# STM32WBA25xx register map
File version: 1.0
Registers are 32-bit, read-write, reset 0x0 unless marked. A register's access mark holds for its fields unless they carry their own. Offsets are from the block's base; [hi:lo] are bit positions; {n}, {i} and the like mark numbered series.

## PKA
Base 0x420C2000
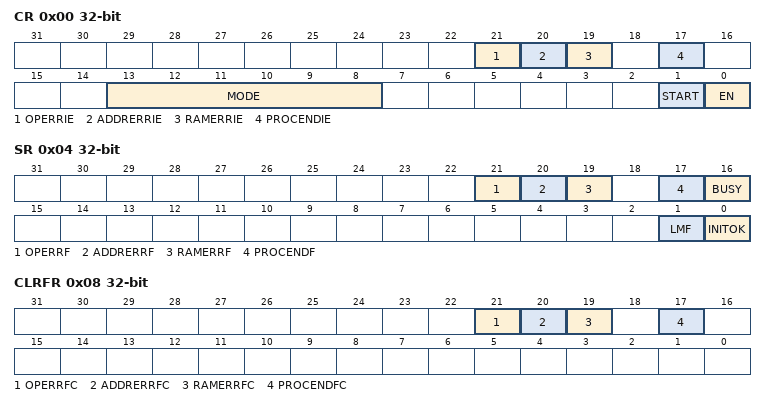
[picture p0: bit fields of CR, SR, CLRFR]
0x00 CR — PKA control register
  [21] OPERRIE — Operation Error interrupt enable
  [20] ADDRERRIE — Address error interrupt enable
  [19] RAMERRIE — RAM error interrupt enable
  [17] PROCENDIE — End of operation interrupt enable
  [13:8] MODE — MODE[5:0] PKA operation code
  [1] START — Start operation
  [0] EN — PKA enable
0x04 SR — PKA status register
  [21] OPERRF — PKA operation Error flag
  [20] ADDRERRF — Address error flag
  [19] RAMERRF — PKA RAM error flag
  [17] PROCENDF — PKA end of operation flag
  [16] BUSY — PKA operation is in progress
  [1] LMF — LMF (Limited mode flag)
  [0] INITOK — PKA initialisation flag
0x08 CLRFR — PKA clear flag register
  [21] OPERRFC — Clear PKA operation Error flag
  [20] ADDRERRFC — Clear address error flag
  [19] RAMERRFC — Clear PKA RAM error flag
  [17] PROCENDFC — Clear PKA end of operation flag
{0x400+4i} RAM[{i}] (i=0..1333)

## DLYB1
Base 0x420CF000
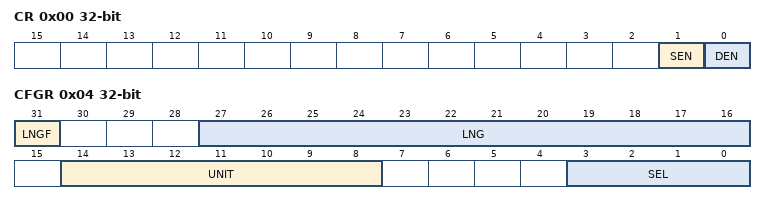
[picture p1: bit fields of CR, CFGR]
0x00 CR — DLYB control register
  [1] SEN — Sampler length enable bit
  [0] DEN — Delay block enable bit
0x04 CFGR — DLYB configuration register
  [31] LNGF — Length valid flag
  [27:16] LNG — Delay line length value
  [14:8] UNIT — Delay of a unit delay cell
  [3:0] SEL — Phase for the output clock

## XSPI1 — XSPI register block
Base 0x420D1400
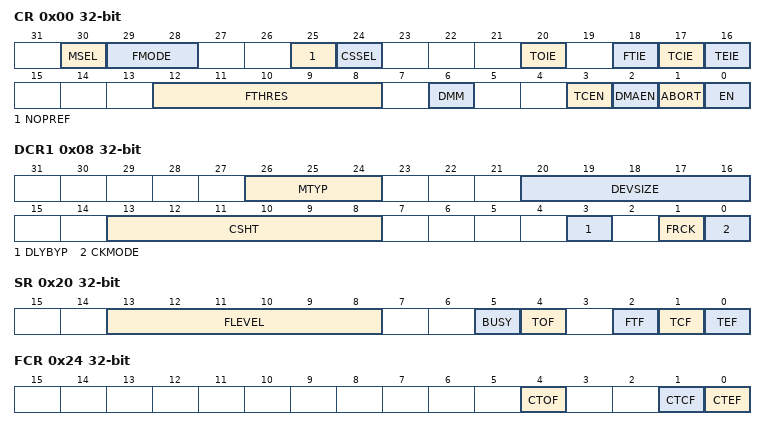
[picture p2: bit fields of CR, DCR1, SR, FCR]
0x00 CR — XSPI control register
  [30] MSEL — Flash Select
  [29:28] FMODE — FMODE[1:0] bits (Functional mode)
  [25] NOPREF — No Prefetch Data
  [24] CSSEL — Chip Select Selection
  [20] TOIE — TOIE (Timeout interrupt enable)
  [18] FTIE — FTIE (FIFO threshold interrupt enable)
  [17] TCIE — TCIE (Transfer complete interrupt enable)
  [16] TEIE — TEIE (Transfer error interrupt enable)
  [12:8] FTHRES — FTHRES[4:0] bits (FIFO threshold level)
  [6] DMM — DMM (Dual-memory configuration)
  [3] TCEN — TCEN (Timeout counter enable)
  [2] DMAEN — DMAEN (DMA enable)
  [1] ABORT — ABORT (Abort request)
  [0] EN — EN (Enable)
0x08 DCR1 — XSPI device configuration register 1
  [26:24] MTYP — MTYP[2:0] bits (Memory type)
  [20:16] DEVSIZE — DEVSIZE[4:0] bits (Device size)
  [13:8] CSHT — CSHT[5:0] bits (Chip-select high time)
  [3] DLYBYP — DLYBYP (Delay block bypass)
  [1] FRCK — FRCK (Free running clock)
  [0] CKMODE — CKMODE (Clock mode 0/mode 3)
0x0C DCR2 — XSPI device configuration register 2
  [7:0] PRESCALER — PRESCALER[7:0] bits (Clock prescaler)
0x20 SR — XSPI status register
  [13:8] FLEVEL — FLEVEL[5:0] bits (FIFO level)
  [5] BUSY — BUSY (Busy)
  [4] TOF — TOF (Timeout flag)
  [2] FTF — FTF (FIFO threshold flag)
  [1] TCF — TCF (Transfer complete flag)
  [0] TEF — TEF (Transfer error flag)
0x24 FCR — XSPI flag clear register
  [4] CTOF — CTOF (Clear timeout flag)
  [1] CTCF — CTCF (Clear transfer complete flag)
  [0] CTEF — CTEF (Clear transfer error flag)
0x40 DLR — XSPI data length register
  [31:0] DL — DL[31:0] bits (Data length)
0x48 AR — XSPI address register
  [31:0] ADDRESS — ADDRESS[31:0] bits (Address)
0x50 DR — XSPI data register
  [31:0] DATA — DATA[31:0] bits (Data)
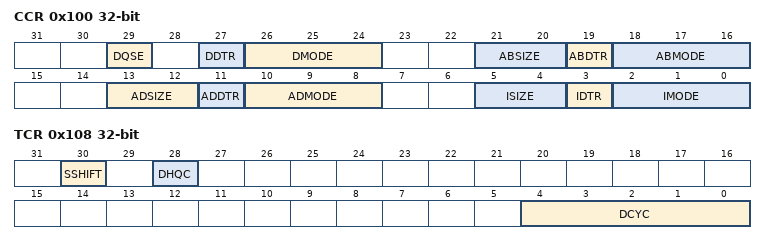
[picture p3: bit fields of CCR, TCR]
0x100 CCR — XSPI communication configuration register
  [29] DQSE — DQSE (DQS enable)
  [27] DDTR — DDTR (Data double transfer rate)
  [26:24] DMODE — DMODE[2:0] bits (Data mode)
  [21:20] ABSIZE — ABSIZE[1:0] bits (Alternate-byte size)
  [19] ABDTR — ABDTR (Alternate- byte double transfer rate)
  [18:16] ABMODE — ABMODE[2:0] bits (Alternate-byte mode)
  [13:12] ADSIZE — ADSIZE[1:0] bits (Address size)
  [11] ADDTR — ADDTR (Address double transfer rate)
  [10:8] ADMODE — ADMODE[2:0] bits (Address mode)
  [5:4] ISIZE — ISIZE[1:0] bits (Instruction size)
  [3] IDTR — IDTR (Instruction double transfer rate)
  [2:0] IMODE — IMODE[2:0] bits (Instruction mode)
0x108 TCR — XSPI timing configuration register
  [30] SSHIFT — SSHIFT (Sample shift)
  [28] DHQC — DHQC (Delay hold quarter cycle)
  [4:0] DCYC — DCYC[4:0] bits (Number of dummy cycles)
0x110 IR — XSPI instruction register
  [31:0] INSTRUCTION — INSTRUCTION[31:0] bits (Instruction)
0x120 ABR — XSPI alternate bytes register
  [31:0] ALTERNATE — ALTERNATE[31:0] bits (Alternate bytes)
0x130 LPTR — XSPI low-power timeout register
  [15:0] TIMEOUT — TIMEOUT[15:0] bits (Timeout period)
